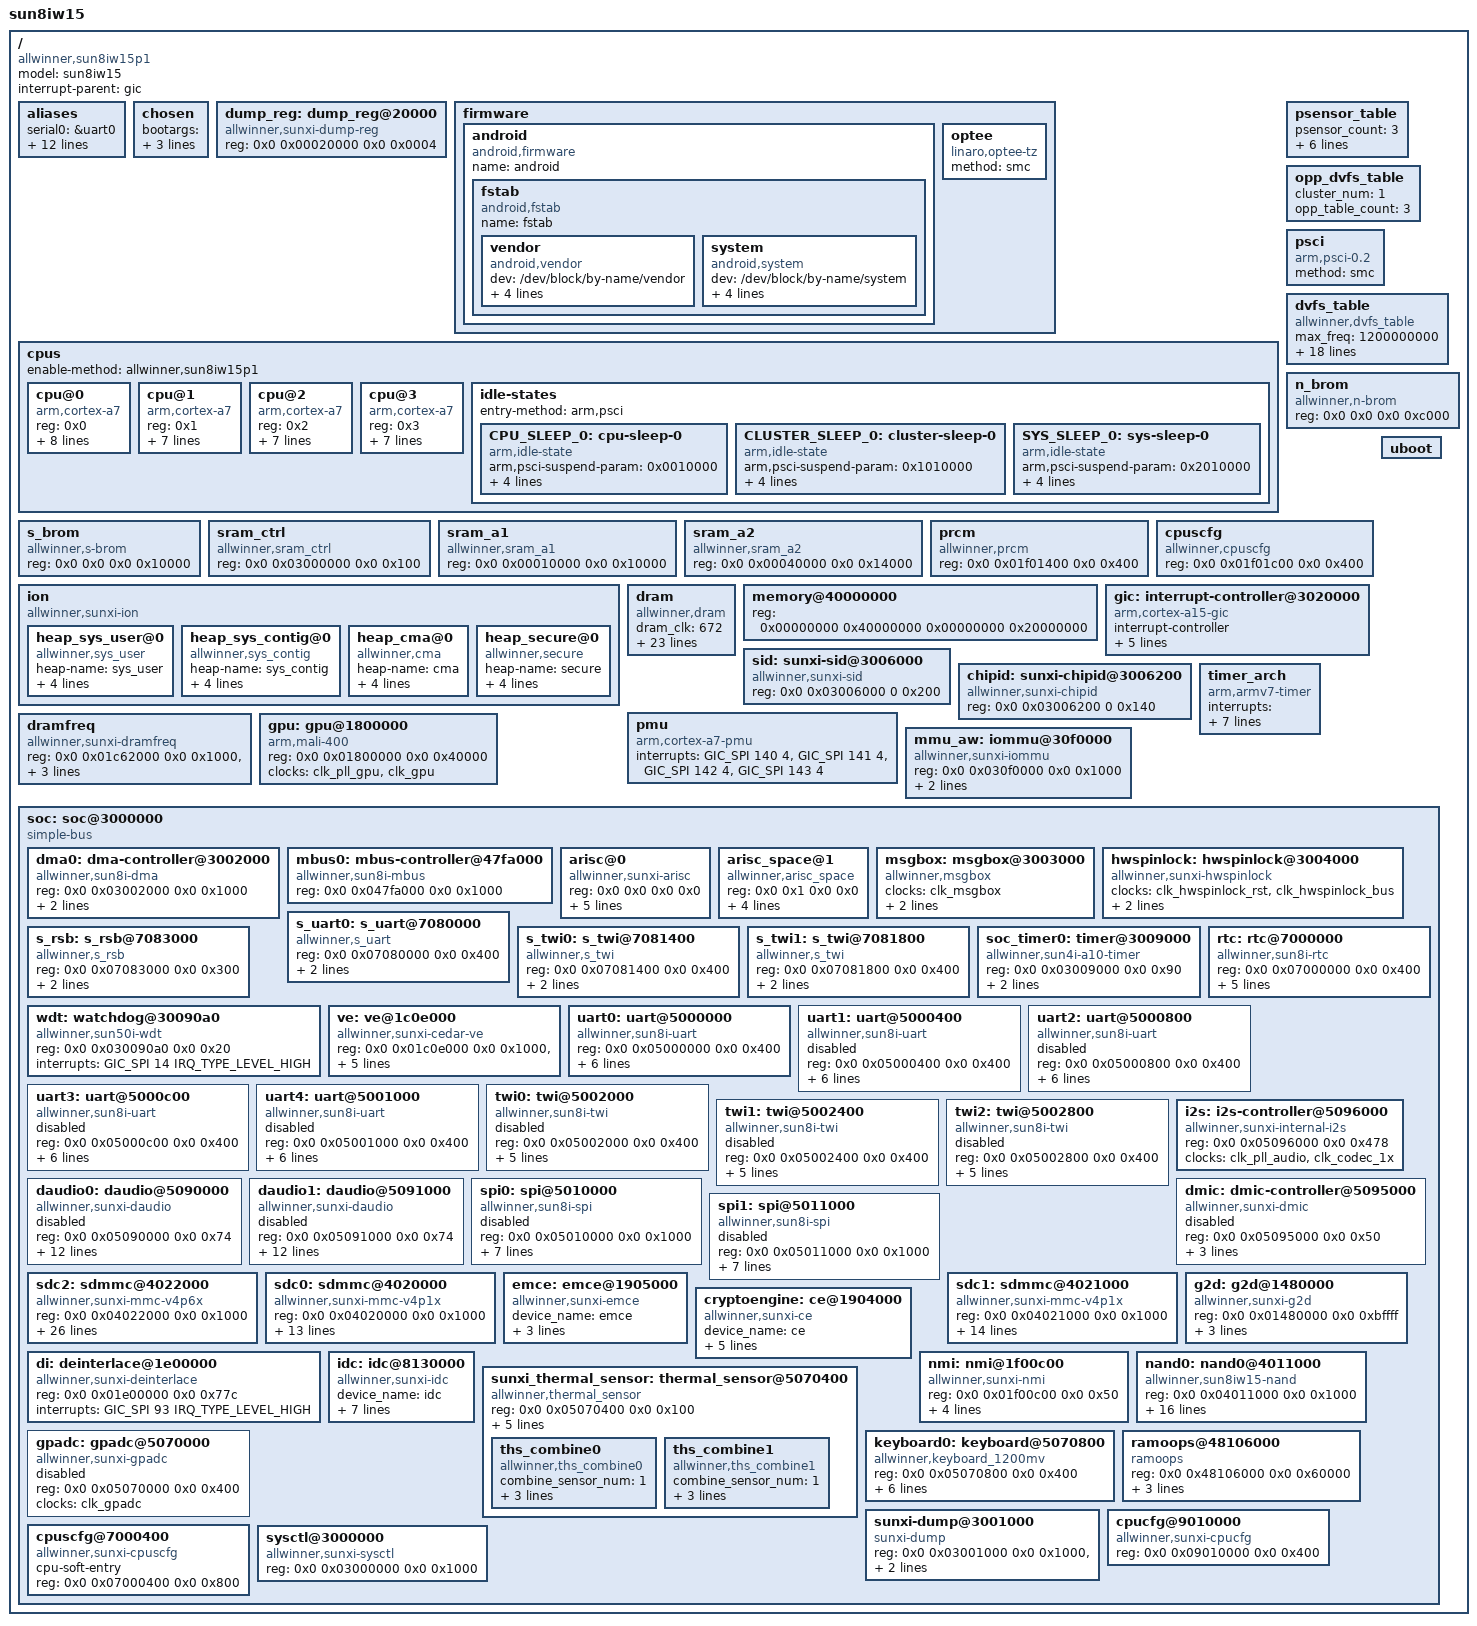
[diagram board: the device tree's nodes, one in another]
/*
 * Allwinner Technology CO., Ltd. sun8iw15p1 platform
 *
 * modify base on juno.dts
 */

/* kernel used */
/memreserve/ 0x40020000 0x00001000; /* super standby range        : [0x40020000~0x41021000], size = 4K  */
/memreserve/ 0x48000000 0x01000000; /* atf                        : [0x48000000~0x49000000], size = 16M */

/* tf used */
/memreserve/ 0x48100000 0x00004000; /* arisc dram code space range: [0x48100000~0x48104000], size = 16K */
/memreserve/ 0x48104000 0x00001000; /* arisc para cfg range       : [0x48104000~0x48105000], size = 4K  */
/memreserve/ 0x48105000 0x00001000; /* arisc message pool range   : [0x48105000~0x48106000], size = 4K  */
/* ramoops used */
/memreserve/ 0x48106000 0x00060000; /* ramoops range              : [0x48106000~0x48166000], size = 384K */

#include <dt-bindings/interrupt-controller/arm-gic.h>
#include <dt-bindings/gpio/gpio.h>
#include "sun8iw15p1-clk.dtsi"
#include "sun8iw15p1-pinctrl.dtsi"
/ {
	model = "sun8iw15";
	compatible = "allwinner,sun8iw15p1";
	interrupt-parent = <&gic>;
	#address-cells = <2>;
	#size-cells = <2>;

	aliases {
		serial0 = &uart0;
		serial1 = &uart1;
		serial2 = &uart2;
		serial3 = &uart3;
		serial4 = &uart4;
		twi0 = &twi0;
		twi1 = &twi1;
		twi2 = &twi2;
		spi0 = &spi0;
		spi1 = &spi1;
		mmc0 = &sdc0;
		mmc2 = &sdc2;
		nand0 =&nand0;
	};

	chosen {
		bootargs = "earlyprintk=sunxi-uart,0x01c28000 loglevel=8 initcall_debug=1 console=ttyS0 init=/init";
		linux,initrd-start = <0x0 0x0>;
		linux,initrd-end = <0x0 0x0>;
	};

	dump_reg: dump_reg@20000 {
		compatible = "allwinner,sunxi-dump-reg";
		reg = <0x0 0x00020000 0x0 0x0004>;
		/* 0x00020000: dump_reg test addr, 0x0004: dump_reg test size */
	};

	firmware {
		android {
			compatible = "android,firmware";
			name = "android";
			fstab {
				compatible = "android,fstab";
				name = "fstab";
				vendor {
					compatible = "android,vendor";
					dev = "/dev/block/by-name/vendor";
					fsmgr_flags = "wait";
					mnt_flags = "ro,barrier=1";
					name = "vendor";
					status = "ok";
					type = "ext4";
				};
				system {
					compatible = "android,system";
					dev = "/dev/block/by-name/system";
					fsmgr_flags = "wait";
					mnt_flags = "ro,barrier=1";
					name = "system";
					status = "ok";
					type = "ext4";
				};
			};
		};
		optee {
			compatible = "linaro,optee-tz";
			method = "smc";
		};
	};

	cpus {
		enable-method = "allwinner,sun8iw15p1";
		#address-cells = <1>;
		#size-cells = <0>;

		cpu@0 {
			device_type = "cpu";
			compatible = "arm,cortex-a7","arm,armv7";
			reg = <0x0>;
			enable-method = "psci";
			clocks = <&clk_pll_cpu>;
			clock-latency = <2000000>;
			clock-frequency = <1008000000>;
			operating-points-v2 =
			<&cpu_opp_l_table0 &cpu_opp_l_table1 &cpu_opp_l_table2>;
			cpu-idle-states = <&CPU_SLEEP_0 &CLUSTER_SLEEP_0 &SYS_SLEEP_0>;
		};

		cpu@1 {
			device_type = "cpu";
			compatible = "arm,cortex-a7","arm,armv7";
			reg = <0x1>;
			enable-method = "psci";
			clocks = <&clk_pll_cpu>;
			clock-frequency = <1008000000>;
			operating-points-v2 =
			<&cpu_opp_l_table0 &cpu_opp_l_table1 &cpu_opp_l_table2>;
			cpu-idle-states = <&CPU_SLEEP_0 &CLUSTER_SLEEP_0 &SYS_SLEEP_0>;
		};

		cpu@2 {
			device_type = "cpu";
			compatible = "arm,cortex-a7","arm,armv7";
			reg = <0x2>;
			enable-method = "psci";
			clocks = <&clk_pll_cpu>;
			clock-frequency = <1008000000>;
			operating-points-v2 =
			<&cpu_opp_l_table0 &cpu_opp_l_table1 &cpu_opp_l_table2>;
			cpu-idle-states = <&CPU_SLEEP_0 &CLUSTER_SLEEP_0 &SYS_SLEEP_0>;
		};

		cpu@3 {
			device_type = "cpu";
			compatible = "arm,cortex-a7","arm,armv7";
			reg = <0x3>;
			enable-method = "psci";
			clocks = <&clk_pll_cpu>;
			clock-frequency = <1008000000>;
			operating-points-v2 =
			<&cpu_opp_l_table0 &cpu_opp_l_table1 &cpu_opp_l_table2>;
			cpu-idle-states = <&CPU_SLEEP_0 &CLUSTER_SLEEP_0 &SYS_SLEEP_0>;
		};

		idle-states {
			entry-method = "arm,psci";

			CPU_SLEEP_0: cpu-sleep-0 {
				compatible = "arm,idle-state";
				arm,psci-suspend-param = <0x0010000>;
				entry-latency-us = <140>;
				exit-latency-us = <540>;
				min-residency-us = <4800>;
				local-timer-stop;
			};

			CLUSTER_SLEEP_0: cluster-sleep-0 {
				compatible = "arm,idle-state";
				arm,psci-suspend-param = <0x1010000>;
				entry-latency-us = <500>;
				exit-latency-us = <1000>;
				min-residency-us = <10000>;
				local-timer-stop;
			};

			SYS_SLEEP_0: sys-sleep-0 {
				compatible = "arm,idle-state";
				arm,psci-suspend-param = <0x2010000>;
				entry-latency-us = <2000000>;
				exit-latency-us = <2000000>;
				min-residency-us = <2000000>;
				local-timer-stop;
			};
		};
	};

	psensor_table: psensor_table {
		psensor_count = <3>;
		prange_min_2 = <6001>;
		prange_max_2 = <7000>;
		prange_min_1 = <4351>;
		prange_max_1 = <6000>;
		prange_min_0 = <0>;
		prange_max_0 = <4350>;
	};

	opp_dvfs_table:opp_dvfs_table {
		cluster_num = <1>;
		opp_table_count = <3>;

	};

	psci {
		compatible = "arm,psci-0.2";
		method = "smc";
	};

	dvfs_table: dvfs_table {
		compatible = "allwinner,dvfs_table";
	};

	n_brom {
		compatible = "allwinner,n-brom";
		reg = <0x0 0x0 0x0 0xc000>;
	};

	s_brom {
		compatible = "allwinner,s-brom";
		reg = <0x0 0x0 0x0 0x10000>;
	};

	sram_ctrl {
		device_type = "sram_ctrl";
		compatible = "allwinner,sram_ctrl";
		reg = <0x0 0x03000000 0x0 0x100>;
	};

	sram_a1 {
		compatible = "allwinner,sram_a1";
		reg = <0x0 0x00010000 0x0 0x10000>;
	};

	sram_a2 {
		compatible = "allwinner,sram_a2";
		reg = <0x0 0x00040000 0x0 0x14000>;
	};

	prcm {
		compatible = "allwinner,prcm";
		reg = <0x0 0x01f01400 0x0 0x400>;
	};

	cpuscfg {
		compatible = "allwinner,cpuscfg";
		reg = <0x0 0x01f01c00 0x0 0x400>;
	};

	ion {
		compatible = "allwinner,sunxi-ion";
		/*
		*types list here:
			ION_HEAP_TYPE_SYSTEM = 0,
			ION_HEAP_TYPE_SYSTEM_CONTIG = 1,
			ION_HEAP_TYPE_CARVEOUT = 2,
			ION_HEAP_TYPE_CHUNK = 3,
			ION_HEAP_TYPE_DMA = 4,
			ION_HEAP_TYPE_SECURE = 6,
		**/
		heap_sys_user@0{
			compatible = "allwinner,sys_user";
			heap-name  = "sys_user";
			heap-id    = <0x0>;
			heap-base  = <0x0>;
			heap-size  = <0x0>;
			heap-type  = "ion_system";
		};
		heap_sys_contig@0{
			compatible = "allwinner,sys_contig";
			heap-name  = "sys_contig";
			heap-id    = <0x1>;
			heap-base  = <0x0>;
			heap-size  = <0x0>;
			heap-type  = "ion_contig";
		};
		heap_cma@0{
			compatible = "allwinner,cma";
			heap-name  = "cma";
			heap-id    = <0x4>;
			heap-base  = <0x0>;
			heap-size  = <0x0>;
			heap-type  = "ion_cma";
		};
		heap_secure@0{
			compatible = "allwinner,secure";
			heap-name  = "secure";
			heap-id    = <0x6>;
			heap-base  = <0x0>;
			heap-size  = <0x0>;
			heap-type  = "ion_secure";
		};
	};

	dram: dram {
		compatible = "allwinner,dram";
		/* clocks = <&clk_pll_ddr>; */
		clock-names = "pll_ddr";
		dram_clk        = <672>;
		dram_type       = <3>;
		dram_zq         = <0x003F3FDD>;
		dram_odt_en     = <1>;
		dram_para1      = <0x10f41000>;
		dram_para2      = <0x00001200>;
		dram_mr0        = <0x1A50>;
		dram_mr1        = <0x40>;
		dram_mr2        = <0x10>;
		dram_mr3        = <0>;
		dram_tpr0       = <0x04E214EA>;
		dram_tpr1       = <0x004214AD>;
		dram_tpr2       = <0x10A75030>;
		dram_tpr3       = <0>;
		dram_tpr4       = <0>;
		dram_tpr5       = <0>;
		dram_tpr6       = <0>;
		dram_tpr7       = <0>;
		dram_tpr8       = <0>;
		dram_tpr9       = <0>;
		dram_tpr10      = <0>;
		dram_tpr11      = <0>;
		dram_tpr12      = <168>;
		dram_tpr13      = <0x823>;
	};

	memory@40000000 {
		device_type = "memory";
		reg = <0x00000000 0x40000000 0x00000000 0x20000000>;
	};

	gic: interrupt-controller@3020000 {
		compatible = "arm,cortex-a15-gic", "arm,cortex-a9-gic";
		#interrupt-cells = <3>;
		#address-cells = <0>;
		device_type = "gic";
		interrupt-controller;
		reg = <0x0 0x03021000 0 0x1000>, /* GIC Dist */
		      <0x0 0x03022000 0 0x2000>, /* GIC CPU */
		      <0x0 0x03024000 0 0x2000>, /* GIC VCPU Control */
		      <0x0 0x03026000 0 0x2000>; /* GIC VCPU */
		interrupts = <GIC_PPI 9 0xf04>; /* GIC Maintenence IRQ */
	};

	sid: sunxi-sid@3006000 {
		compatible = "allwinner,sunxi-sid";
		device_type = "sid";
		reg = <0x0 0x03006000 0 0x200>;
	};

	chipid: sunxi-chipid@3006200 {
		compatible = "allwinner,sunxi-chipid";
		device_type = "chipid";
		reg = <0x0 0x03006200 0 0x140>;
	};

	timer_arch {
		compatible = "arm,armv7-timer";
		interrupts = <GIC_PPI 13 (GIC_CPU_MASK_SIMPLE(4) | IRQ_TYPE_LEVEL_LOW)>,
			     <GIC_PPI 14 (GIC_CPU_MASK_SIMPLE(4) | IRQ_TYPE_LEVEL_LOW)>,
			     <GIC_PPI 11 (GIC_CPU_MASK_SIMPLE(4) | IRQ_TYPE_LEVEL_LOW)>,
			     <GIC_PPI 10 (GIC_CPU_MASK_SIMPLE(4) | IRQ_TYPE_LEVEL_LOW)>;
		clock-frequency = <24000000>;
		arm,cpu-registers-not-fw-configured;
		arm,no-tick-in-suspend;
	};

	pmu {
		compatible = "arm,cortex-a7-pmu";
		interrupts = <GIC_SPI 140 4>,
			     <GIC_SPI 141 4>,
			     <GIC_SPI 142 4>,
			     <GIC_SPI 143 4>;
	};

	dvfs_table: dvfs_table {
		compatible = "allwinner,dvfs_table";
		max_freq = <1200000000>;
		min_freq = <480000000>;
		lv_count = <8>;
		lv1_freq = <1200000000>;
		lv1_volt = <1300>;
		lv2_freq = <1008000000>;
		lv2_volt = <1200>;
		lv3_freq = <816000000>;
		lv3_volt = <1100>;
		lv4_freq = <648000000>;
		lv4_volt = <1040>;
		lv5_freq = <0>;
		lv5_volt = <1040>;
		lv6_freq = <0>;
		lv6_volt = <1040>;
		lv7_freq = <0>;
		lv7_volt = <1040>;
		lv8_freq = <0>;
		lv8_volt = <1040>;
	};

	dramfreq {
		compatible = "allwinner,sunxi-dramfreq";
		reg = <0x0 0x01c62000 0x0 0x1000>,
		      <0x0 0x01c63000 0x0 0x1000>,
		      <0x0 0x01c20000 0x0 0x800>;
		interrupts = <GIC_SPI 69 0x4>;
		/* clocks = <&clk_pll_ddr>, <&clk_pll_periph0>, <&clk_ahb1>; */
		status = "okay";
	};

	uboot: uboot {
	};

	gpu: gpu@1800000 {
		compatible = "arm,mali-400", "arm,mali-utgard";
		reg = <0x0 0x01800000 0x0 0x40000>;
		/*
		interrupts = <0 62 4>,
			     <0 63 4>,
			     <0 64 4>,
			     <0 65 4>,
			     <0 67 4>,
			     <0 68 4>;
		*/
		interrupt-names = "IRQGP", "IRQGPMMU", "IRQPP0", "IRQPPMMU0", "IRQPP1", "IRQPPMMU1";
		clocks = <&clk_pll_gpu>, <&clk_gpu>;
	};

	mmu_aw: iommu@30f0000 {
		compatible = "allwinner,sunxi-iommu";
		reg = <0x0 0x030f0000 0x0 0x1000>;
		interrupts = <GIC_SPI 18 IRQ_TYPE_LEVEL_HIGH>;
		interrupt-names = "iommu-irq";
		clocks = <&clk_iommu>;
		clock-names = "iommu";
		#iommu-cells = <2>;
		status = "okay";
	};

	soc: soc@3000000 {
		compatible = "simple-bus";
		#address-cells = <2>;
		#size-cells = <2>;
		ranges;
		device_type = "soc";

		dma0:dma-controller@3002000 {
			compatible = "allwinner,sun8i-dma";
			reg = <0x0 0x03002000 0x0 0x1000>;
			interrupts = <GIC_SPI 10 IRQ_TYPE_LEVEL_HIGH>;
			clocks = <&clk_dma>;
			#dma-cells = <1>;
		};

		mbus0:mbus-controller@47fa000{
			compatible = "allwinner,sun8i-mbus";
			reg = <0x0 0x047fa000 0x0 0x1000>;
			#mbus-cells = <1>;
		};

		arisc@0 {
			compatible = "allwinner,sunxi-arisc";
			#address-cells = <2>;
			#size-cells = <2>;
			reg = <0x0 0x0 0x0 0x0>;
			clocks = <&clk_losc>, <&clk_iosc>, <&clk_hosc>, <&clk_pll_periph0>;
			clock-names = "losc", "iosc", "hosc", "pll_periph0";
			powchk_used = <0x0>;
			power_reg = <0x02309621>;
			system_power = <50>;
		};

		arisc_space@1 {
			compatible = "allwinner,arisc_space";
			reg = <0x0 0x1 0x0 0x0>;
			/* num    dst        offset     size                              */
			space1 = <0x00100000 0x00000000 0x00014000>; /* srama2 code space */
			space2 = <0x48100000 0x00018000 0x00004000>; /* dram code space   */
			space3 = <0x48104000 0x00000000 0x00001000>; /* para space        */
			space4 = <0x48105000 0x00000000 0x00001000>; /* msgpool space     */
		};

		msgbox: msgbox@3003000 {
			compatible = "allwinner,msgbox";
			clocks = <&clk_msgbox>;
			clock-names = "clk_msgbox";
			reg = <0x0 0x03003000 0x0 0x1000>;
			interrupts = <GIC_SPI 11 IRQ_TYPE_EDGE_RISING>;
			status = "okay";
		};

		hwspinlock: hwspinlock@3004000 {
			compatible = "allwinner,sunxi-hwspinlock";
			clocks = <&clk_hwspinlock_rst>, <&clk_hwspinlock_bus>;
			clock-names = "clk_hwspinlock_rst", "clk_hwspinlock_bus";
			reg = <0x0 0x03004000 0x0 0x1000>;
			num-locks = <8>; /* the number hwspinlock we needed, max 32 */
			status = "okay";
		};

		s_uart0: s_uart@7080000 {
			compatible = "allwinner,s_uart";
			reg = <0x0 0x07080000 0x0 0x400>;
			interrupts = <GIC_SPI 131 IRQ_TYPE_LEVEL_HIGH>;
			pinctrl-names = "default";
			pinctrl-0 = <&s_uart0_pins_a>;
			status = "okay";
		};

		s_rsb: s_rsb@7083000 {
			compatible = "allwinner,s_rsb";
			reg = <0x0 0x07083000 0x0 0x300>;
			interrupts = <GIC_SPI 140 IRQ_TYPE_LEVEL_HIGH>;
			pinctrl-names = "default";
			pinctrl-0 = <&s_rsb0_pins_a>;
			status = "okay";
		};

		s_twi0: s_twi@7081400 {
			compatible = "allwinner,s_twi";
			reg = <0x0 0x07081400 0x0 0x400>;
			interrupts = <GIC_SPI 132 IRQ_TYPE_LEVEL_HIGH>;
			pinctrl-names = "default";
			pinctrl-0 = <&s_twi0_pins_a>;
			status = "okay";
		};

		s_twi1: s_twi@7081800 {
			compatible = "allwinner,s_twi";
			reg = <0x0 0x07081800 0x0 0x400>;
			interrupts = <GIC_SPI 133 IRQ_TYPE_LEVEL_HIGH>;
			pinctrl-names = "default";
			pinctrl-0 = <&s_twi0_pins_a>;
			status = "okay";
		};

		soc_timer0: timer@3009000 {
			compatible = "allwinner,sun4i-a10-timer";
			device_type = "timer";
			reg = <0x0 0x03009000 0x0 0x90>;
			interrupts = <GIC_SPI 50 IRQ_TYPE_LEVEL_HIGH>;
			/* On FPGA, timer can only use the losc.
			 * On IC, timer should use the hosc.
			 */
			clocks = <&clk_hosc>, <&clk_losc>;
		};

		rtc: rtc@7000000 {
			compatible = "allwinner,sun8i-rtc", \
				      "allwinner,sunxi-rtc";
			device_type = "rtc";
			reg = <0x0 0x07000000 0x0 0x400>;
			interrupts = <GIC_SPI 89 IRQ_TYPE_LEVEL_HIGH>;
			gpr_offset = <0x100>;
			gpr_len	   = <8>;
			gpr_cur_pos = <6>;
			wakeup-source;
		};

		wdt: watchdog@30090a0 {
			compatible = "allwinner,sun50i-wdt";
			reg = <0x0 0x030090a0 0x0 0x20>;
			interrupts = <GIC_SPI 14 IRQ_TYPE_LEVEL_HIGH>;
		};

		ve: ve@1c0e000 {
			compatible = "allwinner,sunxi-cedar-ve";
			reg = <0x0 0x01c0e000 0x0 0x1000>,
			      <0x0 0x03000000 0x0 0x10>,
			      <0x0 0x03001000 0x0 0x1000>;
			interrupts = <GIC_SPI 25 4>;
			clocks = <&clk_pll_ve>,	<&clk_ve>;
			iommus = <&mmu_aw 3 1>;
		};

		uart0: uart@5000000 {
			compatible = "allwinner,sun8i-uart";
			device_type = "uart0";
			reg = <0x0 0x05000000 0x0 0x400>;
			interrupts = <GIC_SPI 41 IRQ_TYPE_LEVEL_HIGH>;
			clocks = <&clk_uart0>;
			pinctrl-names = "default", "sleep";
			pinctrl-0 = <&uart0_pins_a>;
			pinctrl-1 = <&uart0_pins_b>;
			uart0_port = <0>;
			uart0_type = <2>;
			status = "okay";
		};

		uart1: uart@5000400 {
			compatible = "allwinner,sun8i-uart";
			device_type = "uart1";
			reg = <0x0 0x05000400 0x0 0x400>;
			interrupts = <GIC_SPI 42 IRQ_TYPE_LEVEL_HIGH>;
			clocks = <&clk_uart1>;
			pinctrl-names = "default", "sleep";
			pinctrl-0 = <&uart1_pins_a>;
			pinctrl-1 = <&uart1_pins_b>;
			uart1_port = <1>;
			uart1_type = <4>;
			status = "disabled";
		};

		uart2: uart@5000800 {
			compatible = "allwinner,sun8i-uart";
			device_type = "uart2";
			reg = <0x0 0x05000800 0x0 0x400>;
			interrupts = <GIC_SPI 43 IRQ_TYPE_LEVEL_HIGH>;
			clocks = <&clk_uart2>;
			pinctrl-names = "default", "sleep";
			pinctrl-0 = <&uart2_pins_a>;
			pinctrl-1 = <&uart2_pins_b>;
			uart2_port = <2>;
			uart2_type = <4>;
			status = "disabled";
		};

		uart3: uart@5000c00 {
			compatible = "allwinner,sun8i-uart";
			device_type = "uart3";
			reg = <0x0 0x05000c00 0x0 0x400>;
			interrupts = <GIC_SPI 44 IRQ_TYPE_LEVEL_HIGH>;
			clocks = <&clk_uart3>;
			pinctrl-names = "default", "sleep";
			pinctrl-0 = <&uart3_pins_a>;
			pinctrl-1 = <&uart3_pins_b>;
			uart3_port = <3>;
			uart3_type = <4>;
			status = "disabled";
		};

		uart4: uart@5001000 {
			compatible = "allwinner,sun8i-uart";
			device_type = "uart4";
			reg = <0x0 0x05001000 0x0 0x400>;
			interrupts = <GIC_SPI 45 IRQ_TYPE_LEVEL_HIGH>;
			clocks = <&clk_uart4>;
			pinctrl-names = "default", "sleep";
			pinctrl-0 = <&uart4_pins_a>;
			pinctrl-1 = <&uart4_pins_b>;
			uart4_port = <4>;
			uart4_type = <4>;
			status = "disabled";
		};

		twi0: twi@5002000{
			#address-cells = <1>;
			#size-cells = <0>;
			compatible = "allwinner,sun8i-twi";
			device_type = "twi0";
			reg = <0x0 0x05002000 0x0 0x400>;
			interrupts = <GIC_SPI 34 IRQ_TYPE_LEVEL_HIGH>;
			clocks = <&clk_twi0>;
			clock-frequency = <400000>;
			pinctrl-names = "default", "sleep";
			pinctrl-0 = <&twi0_pins_a>;
			pinctrl-1 = <&twi0_pins_b>;
			status = "disabled";
		};

		twi1: twi@5002400{
			#address-cells = <1>;
			#size-cells = <0>;
			compatible = "allwinner,sun8i-twi";
			device_type = "twi1";
			reg = <0x0 0x05002400 0x0 0x400>;
			interrupts = <GIC_SPI 35 IRQ_TYPE_LEVEL_HIGH>;
			clocks = <&clk_twi1>;
			clock-frequency = <100000>;
			pinctrl-names = "default", "sleep";
			pinctrl-0 = <&twi1_pins_a>;
			pinctrl-1 = <&twi1_pins_b>;
			status = "disabled";
		};

		twi2: twi@5002800{
			#address-cells = <1>;
			#size-cells = <0>;
			compatible = "allwinner,sun8i-twi";
			device_type = "twi2";
			reg = <0x0 0x05002800 0x0 0x400>;
			interrupts = <GIC_SPI 36 IRQ_TYPE_LEVEL_HIGH>;
			clocks = <&clk_twi2>;
			clock-frequency = <100000>;
			pinctrl-names = "default", "sleep";
			pinctrl-0 = <&twi2_pins_a>;
			pinctrl-1 = <&twi2_pins_b>;
			status = "disabled";
		};

		i2s:i2s-controller@5096000 {
			compatible = "allwinner,sunxi-internal-i2s";
			reg = <0x0 0x05096000 0x0 0x478>;/*digital baseadress*/
			clocks = <&clk_pll_audio>,<&clk_codec_1x>;
			status = "okay";
		};

		daudio0:daudio@5090000 {
			compatible = "allwinner,sunxi-daudio";
			reg = <0x0 0x05090000 0x0 0x74>;
			clocks = <&clk_pll_audio>,<&clk_i2s0>;
			pinctrl-names = "default","sleep";
			pinctrl-0 = <&daudio0_pins_a>;
			pinctrl-1 = <&daudio0_pins_b>;
			pcm_lrck_period =  <0x80>;
			slot_width_select =  <0x20>;
			daudio_master =  <0x04>;
			audio_format =  <0x01>;
			signal_inversion =  <0x01>;
			frametype = <0x00>;
			tdm_config =  <0x01>;
			tdm_num = <0x0>;
			mclk_div = <0x0>;
			status = "disabled";
		};

		daudio1:daudio@5091000 {
			compatible = "allwinner,sunxi-daudio";
			reg = <0x0 0x05091000 0x0 0x74>;
			clocks = <&clk_pll_audio>,<&clk_i2s1>;
			pinctrl-names = "default","sleep";
			pinctrl-0 = <&daudio1_pins_a>;
			pinctrl-1 = <&daudio1_pins_b>;
			pcm_lrck_period =  <0x20>;
			slot_width_select =  <0x20>;
			daudio_master =  <0x04>;
			audio_format =  <0x01>;
			signal_inversion =  <0x01>;
			frametype = <0x00>;
			tdm_config =  <0x01>;
			tdm_num = <0x1>;
			mclk_div = <0x0>;
			status = "disabled";
		};

		dmic:dmic-controller@5095000{
			compatible = "allwinner,sunxi-dmic";
			reg = <0x0 0x05095000 0x0 0x50>;
			clocks = <&clk_pll_audio>,<&clk_dmic>;
			pinctrl-names = "default","sleep";
			pinctrl-0 = <&dmic_pins_a>;
			pinctrl-1 = <&dmic_pins_b>;
			status = "disabled";
		};

		spi0: spi@5010000 {
			#address-cells = <1>;
			#size-cells = <0>;
			compatible = "allwinner,sun8i-spi";
			device_type = "spi0";
			reg = <0x0 0x05010000 0x0 0x1000>;
			interrupts = <GIC_SPI 46 IRQ_TYPE_LEVEL_HIGH>;
			clocks = <&clk_pll_periph0>, <&clk_spi0>;
			clock-frequency = <100000000>;
			pinctrl-names = "default", "sleep";
			pinctrl-0 = <&spi0_pins_a &spi0_pins_b>;
			pinctrl-1 = <&spi0_pins_c>;
			spi0_cs_number = <2>;
			spi0_cs_bitmap = <3>;
			status = "disabled";
		};

		spi1: spi@5011000 {
			#address-cells = <1>;
			#size-cells = <0>;
			compatible = "allwinner,sun8i-spi";
			device_type = "spi1";
			reg = <0x0 0x05011000 0x0 0x1000>;
			interrupts = <GIC_SPI 47 IRQ_TYPE_LEVEL_HIGH>;
			clocks = <&clk_pll_periph0>, <&clk_spi1>;
			clock-frequency = <100000000>;
			pinctrl-names = "default", "sleep";
			pinctrl-0 = <&spi1_pins_a &spi1_pins_b>;
			pinctrl-1 = <&spi1_pins_c>;
			spi1_cs_number = <1>;
			spi1_cs_bitmap = <1>;
			status = "disabled";
		};

		sdc2: sdmmc@4022000 {
			compatible = "allwinner,sunxi-mmc-v4p6x";
			device_type = "sdc2";
			reg = <0x0 0x04022000 0x0 0x1000>;
			interrupts = <GIC_SPI 40 IRQ_TYPE_LEVEL_HIGH>;
			clocks = <&clk_hosc>,
				 <&clk_pll_periph1x2>,
				 <&clk_sdmmc2_mod>,
				 <&clk_sdmmc2_bus>,
				 <&clk_sdmmc2_rst>;
			clock-names = "osc24m","pll_periph","mmc","ahb","rst";
			pinctrl-names = "default","sleep";
			pinctrl-0 = <&sdc2_pins_a>;
			pinctrl-1 = <&sdc2_pins_b>;
			bus-width = <8>;
			cap-mmc-highspeed;
			cap-cmd23;
			mmc-cache-ctrl;
			/*mmc-ddr-1_8v;*/
			/*mmc-hs200-1_8v;*/
			/*mmc-hs400-1_8v;*/
			non-removable;
			/*max-frequency = <200000000>;*/
			max-frequency = <50000000>;
			cap-erase;
			mmc-high-capacity-erase-size;
			no-sdio;
			no-sd;
			/*-- speed mode --*/
			/*sm0: DS26_SDR12*/
			/*sm1: HSSDR52_SDR25*/
			/*sm2: HSDDR52_DDR50*/
			/*sm3: HS200_SDR104*/
			/*sm4: HS400*/
			/*-- frequency point --*/
			/*f0: CLK_400K*/
			/*f1: CLK_25M*/
			/*f2: CLK_50M*/
			/*f3: CLK_100M*/
			/*f4: CLK_150M*/
			/*f5: CLK_200M*/

			sdc_tm4_sm0_freq0 = <0>;
			sdc_tm4_sm0_freq1 = <0>;
			sdc_tm4_sm1_freq0 = <0x00000000>;
			sdc_tm4_sm1_freq1 = <0>;
			sdc_tm4_sm2_freq0 = <0x00000000>;
			sdc_tm4_sm2_freq1 = <0>;
			sdc_tm4_sm3_freq0 = <0x05000000>;
			sdc_tm4_sm3_freq1 = <0x00000005>;
			sdc_tm4_sm4_freq0 = <0x00050000>;
			sdc_tm4_sm4_freq1 = <0x00000004>;

			/*vmmc-supply = <&reg_3p3v>;*/
			/*vqmc-supply = <&reg_3p3v>;*/
			/*vdmc-supply = <&reg_3p3v>;*/
			/*vmmc = "vcc-card";*/
			/*vqmc = "";*/
			/*vdmc = "";*/
			/*sunxi-power-save-mode;*/
			/*status = "disabled";*/
			status = "okay";
		};

		sdc0: sdmmc@4020000 {
			compatible = "allwinner,sunxi-mmc-v4p1x";
			device_type = "sdc0";
			reg = <0x0 0x04020000 0x0 0x1000>;
			interrupts = <GIC_SPI 38 IRQ_TYPE_LEVEL_HIGH>;
			clocks = <&clk_hosc>,
				 <&clk_pll_periph1x2>,
				 <&clk_sdmmc0_mod>,
				 <&clk_sdmmc0_bus>,
				 <&clk_sdmmc0_rst>;
			clock-names = "osc24m","pll_periph","mmc","ahb","rst";
			pinctrl-names = "default","sleep","uart_jtag";
			pinctrl-0 = <&sdc0_pins_a>;
			pinctrl-1 = <&sdc0_pins_b>;
			pinctrl-2 = <&sdc0_pins_c>;
			max-frequency = <50000000>;
			bus-width = <4>;
			/*non-removable;*/
			/*broken-cd;*/
			/*cd-inverted*/
			/*cd-gpios = <&pio PF 6 0 1 2 0>;*/
			/* vmmc-supply = <&reg_3p3v>;*/
			/* vqmc-supply = <&reg_3p3v>;*/
			/* vdmc-supply = <&reg_3p3v>;*/
			/*vmmc = "vcc-card";*/
			/*vqmc = "";*/
			/*vdmc = "";*/
			cap-sd-highspeed;
			cap-wait-while-busy;
			no-sdio;
			no-mmc;
			/*sd-uhs-sdr50;*/
			/*sd-uhs-ddr50;*/
			/*cap-sdio-irq;*/
			/*keep-power-in-suspend;*/
			/*ignore-pm-notify;*/
			/*sunxi-power-save-mode;*/
			/*sunxi-dly-400k = <1 0 0 0>; */
			/*sunxi-dly-26M  = <1 0 0 0>;*/
			/*sunxi-dly-52M  = <1 0 0 0>;*/
			/*sunxi-dly-52M-ddr4  = <1 0 0 0>;*/
			/*sunxi-dly-52M-ddr8  = <1 0 0 0>;*/
			/*sunxi-dly-104M  = <1 0 0 0>;*/
			/*sunxi-dly-208M  = <1 0 0 0>;*/
			/*sunxi-dly-104M-ddr  = <1 0 0 0>;*/
			/*sunxi-dly-208M-ddr  = <1 0 0 0>;*/

			status = "okay";
		};

		sdc1: sdmmc@4021000 {
			compatible = "allwinner,sunxi-mmc-v4p1x";
			device_type = "sdc1";
			reg = <0x0 0x04021000 0x0 0x1000>;
			interrupts = <GIC_SPI 39 IRQ_TYPE_LEVEL_HIGH>;
			clocks = <&clk_hosc>,
				 <&clk_pll_periph1x2>,
				 <&clk_sdmmc1_mod>,
				 <&clk_sdmmc1_bus>,
				 <&clk_sdmmc1_rst>;
			clock-names = "osc24m","pll_periph","mmc","ahb","rst";
			pinctrl-names = "default","sleep";
			pinctrl-0 = <&sdc1_pins_a>;
			pinctrl-1 = <&sdc1_pins_b>;
			max-frequency = <50000000>;
			bus-width = <4>;
			/*broken-cd;*/
			/*cd-inverted*/
			/*cd-gpios = <&pio PG 6 6 1 2 0>;*/
			/* vmmc-supply = <&reg_3p3v>;*/
			/* vqmc-supply = <&reg_3p3v>;*/
			/* vdmc-supply = <&reg_3p3v>;*/
			/*vmmc = "vcc-card";*/
			/*vqmc = "";*/
			/*vdmc = "";*/
			cap-sd-highspeed;
			no-mmc;
			/*sd-uhs-sdr50;*/
			/*sd-uhs-ddr50;*/
			/*sd-uhs-sdr104;*/
			/*cap-sdio-irq;*/
			keep-power-in-suspend;
			/*ignore-pm-notify;*/
			/*sunxi-power-save-mode;*/
			/*sunxi-dly-400k = <1 0 0 0 0>; */
			/*sunxi-dly-26M  = <1 0 0 0 0>;*/
			/*sunxi-dly-52M  = <1 0 0 0 0>;*/
			sunxi-dly-52M-ddr4  = <1 0 0 0 2>;
			/*sunxi-dly-52M-ddr8  = <1 0 0 0 0>;*/
			sunxi-dly-104M  = <1 0 0 0 1>;
			/*sunxi-dly-208M  = <1 1 0 0 0>;*/
			sunxi-dly-208M  = <1 0 0 0 1>;
			/*sunxi-dly-104M-ddr  = <1 0 0 0 0>;*/
			/*sunxi-dly-208M-ddr  = <1 0 0 0 0>;*/

			status = "okay";
			/*status = "disabled";*/
		};

		g2d: g2d@1480000 {
			compatible = "allwinner,sunxi-g2d";
			reg = <0x0 0x01480000 0x0 0xbffff>;
			interrupts = <GIC_SPI 21 0x4>;
			clocks = <&clk_g2d>;
			iommus = <&mmu_aw 5 1>;
			status = "okay";
		};

		emce: emce@1905000 {
			 compatible = "allwinner,sunxi-emce";
			 device_name = "emce";
			 reg = <0x0 0x01905000 0 0x100>;
			 clock-frequency = <300000000>;
			 clocks = <&clk_emce>, <&clk_pll_periph0x2>;
		};

		cryptoengine: ce@1904000 {
			compatible = "allwinner,sunxi-ce";
			device_name = "ce";
			reg = <0x0 0x01904000 0x0 0xa0>,
					<0x0 0x01904800 0x0 0xa0>; /* Unused */
			interrupts = <GIC_SPI 30 0x1>,
					<GIC_SPI 31 0x1>; /* Unused */
			clock-frequency = <300000000>; /* 300MHz */
			clocks = <&clk_ce>, <&clk_pll_periph0x2>;
		};

		di:deinterlace@1e00000{
			#address-cells = <1>;
			#size-cells = <0>;
			compatible = "allwinner,sunxi-deinterlace";
			reg = <0x0 0x01e00000 0x0 0x77c>;
			interrupts = <GIC_SPI 93 IRQ_TYPE_LEVEL_HIGH>;
			/* clocks = <&clk_deinterlace> ,<&clk_pll_periph0>; */
			status = "okay";
		};

		idc:idc@8130000{
			compatible = "allwinner,sunxi-idc";
			device_name = "idc";
			reg = <0x0 0x08130000 0x0 0x338>;
			irq_delay_en = <0x0 0x0 0x0 0x0 0x0 0x0 0x0>;
			irq_channel_array = <
				0x0 0x0 0x0 0x0 0x0 0x0 0x0
				0x0 0x0 0x0 0x0 0x0 0x0 0x0
				0x0 0x0 0x0 0x0 0x0 0x0 0x0
				0x0 0x0 0x0 0x0 0x0 0x0 0x0>;
			channel_delay_cycle = <	0 0 0 0 0 0 0 0
				0 0 0 0 0 0 0 0>;
			wfi_check_en = <0x0>;
			status = "okay";
		};

		nmi:nmi@1f00c00{
			#address-cells = <1>;
			#size-cells = <0>;
			compatible = "allwinner,sunxi-nmi";
			reg = <0x0 0x01f00c00 0x0 0x50>;
			nmi_irq_ctrl = <0x0c>;
			nmi_irq_en = <0x40>;
			nmi_irq_status = <0x10>;
			nmi_irq_mask = <0x50>;
			status = "okay";
		};

		nand0:nand0@4011000 {
			compatible = "allwinner,sun8iw15-nand";
			device_type = "nand0";
			reg = <0x0 0x04011000 0x0 0x1000>; /* nand0 */
			interrupts = <GIC_SPI 28 0x04>;
			clocks = <&clk_pll_periph1x2>,<&clk_nand0>,<&clk_nand1>;
			pinctrl-names = "default", "sleep";
			pinctrl-0 = <&nand0_pins_a &nand0_pins_b>;
			pinctrl-1 = <&nand0_pins_c>;
			nand0_regulator1 = "vcc-nand";
			nand0_regulator2 = "none";
			nand0_cache_level = <0x55aaaa55>;
			nand0_flush_cache_num = <0x55aaaa55>;
			nand0_capacity_level = <0x55aaaa55>;
			nand0_id_number_ctl = <0x55aaaa55>;
			nand0_print_level = <0x55aaaa55>;
			nand0_p0 = <0x55aaaa55>;
			nand0_p1 = <0x55aaaa55>;
			nand0_p2 = <0x55aaaa55>;
			nand0_p3 = <0x55aaaa55>;
			status = "okay";
		};

		sunxi_thermal_sensor:thermal_sensor@5070400{
			compatible = "allwinner,thermal_sensor";
			reg = <0x0 0x05070400 0x0 0x100>;
			/*interrupts = <GIC_SPI 1 IRQ_TYPE_NONE>;*/
			clocks = <&clk_hosc>,<&clk_ths>;
			sensor_num = <2>;
			combine_num = <2>;
			alarm_temp = <100000>;
			shut_temp= <110000>;
			status = "okay";

			ths_combine0:ths_combine0{
				compatible = "allwinner,ths_combine0";
				#thermal-sensor-cells = <1>;
				combine_sensor_num = <1>;
				combine_sensor_type = "CPU";
				combine_sensor_temp_type = "max";
				combine_sensor_id = <0>;
			};

			ths_combine1:ths_combine1{
				compatible = "allwinner,ths_combine1";
				#thermal-sensor-cells = <1>;
				combine_sensor_num = <1>;
				combine_sensor_type = "GPU";
				combine_sensor_temp_type = "max";
				combine_sensor_id = <1>;
			};
		};

		gpadc:gpadc@5070000{
			compatible = "allwinner,sunxi-gpadc";
			reg = <0x0 0x05070000 0x0 0x400>;
			/*interrupts = <GIC_SPI 0 IRQ_TYPE_NONE>;*/
			clocks = <&clk_gpadc>;
			status = "disable";
		};

		keyboard0:keyboard@5070800{
			compatible = "allwinner,keyboard_1200mv";
			reg = <0x0 0x05070800 0x0 0x400>;
			/*interrupts = <GIC_SPI 2 IRQ_TYPE_NONE>;*/
			status = "okay";
			key_cnt = <5>;
			key0 = <115 115>;
			key1 = <235 114>;
			key2 = <330 139>;
			key3 = <420 28>;
			key4 = <520 102>;
		};

		ramoops@48106000 {
			compatible = "ramoops";
			reg = <0x0 0x48106000 0x0 0x60000>;
			record-size  = <0x00020000>;
			console-size = <0x00020000>;
			pmsg-size    = <0x00020000>;
		};

		sunxi-dump@3001000 {
			compatible = "sunxi-dump";
			reg = <0x0 0x03001000 0x0 0x1000>,
			      <0x0 0x03021000 0x0 0x400>;
			group-names = "ccmu", "gic-dist";
		};

		cpucfg@9010000 {
			compatible = "allwinner,sunxi-cpucfg";
			reg = <0x0 0x09010000 0x0 0x400>;
		};

		cpuscfg@7000400 {
			compatible = "allwinner,sunxi-cpuscfg";
			cpu-soft-entry;
			reg = <0x0 0x07000400 0x0 0x800>;
		};

		sysctl@3000000 {
			compatible = "allwinner,sunxi-sysctl";
			reg = <0x0 0x03000000 0x0 0x1000>;
		};
	};
};
